# DA14585 register map
Vendor: Dialog; Series: DA1458x; File version: 1.2
CPU: CM0 r1p0, little endian, MPU, FPU, 3 interrupt priority bits
Registers are 16-bit, read-write, reset 0x0 unless marked. A register's access mark holds for its fields unless they carry their own. Offsets are from the block's base; [hi:lo] are bit positions.

## crg580_nl01 — crg580_nl01 registers
Base 0x50000000
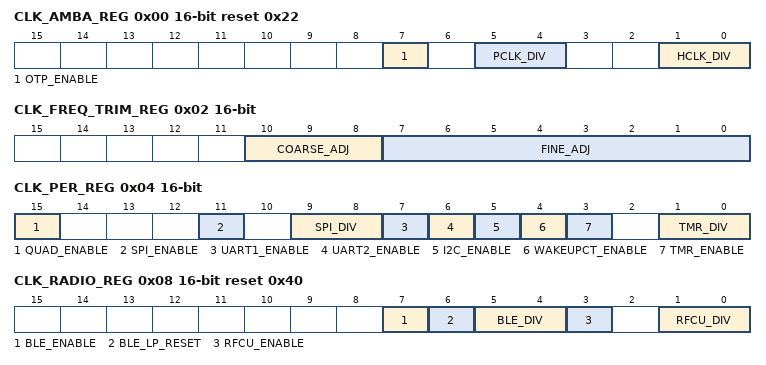
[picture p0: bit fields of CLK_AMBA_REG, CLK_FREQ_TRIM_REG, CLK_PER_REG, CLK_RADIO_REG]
0x00 CLK_AMBA_REG reset 0x22 — HCLK, PCLK, divider and clock gates
  [7] OTP_ENABLE — Clock enable for OTP controller
  [5:4] PCLK_DIV — APB interface clock (PCLK). Divider is cascaded with HCLK_DIV. PCLK is HCLK divided by: 0x0: divide by 1 0x1: divide by 2 0x2: divide by 4 0x3: divide by 8
  [1:0] HCLK_DIV — AHB interface and microprocessor clock (HCLK). HCLK is source clock divided by: 0x0: divide by 1 0x1: divide by 2 0x2: divide by 4 0x3: divide by 8
0x02 CLK_FREQ_TRIM_REG — Xtal frequency trimming register
  [10:8] COARSE_ADJ — Xtal frequency course trimming register. 0x0: lowest frequency 0x7: highest frequencyIncrement or decrement the binary value with 1. Wait approximately 200 us to allow the adjustment to settle.
  [7:0] FINE_ADJ — Xtal frequency fine trimming register. 0x00: lowest frequency 0xFF: highest frequency
0x04 CLK_PER_REG — Peripheral divider register
  [15] QUAD_ENABLE — Enable the Quadrature clock
  [11] SPI_ENABLE — Enable SPI clock
  [9:8] SPI_DIV — Division factor for SPI 0x0: divide by 1 0x1: divide by 2 0x2: divide by 4 0x3: divide by 8
  [7] UART1_ENABLE — Enable UART1 clock
  [6] UART2_ENABLE — Enable UART2 clock
  [5] I2C_ENABLE — Enable I2C clock
  [4] WAKEUPCT_ENABLE — Enable Wakeup CaptureTimer clock
  [3] TMR_ENABLE — Enable TIMER0 and TIMER2 clock
  [1:0] TMR_DIV — Division factor for TIMER0 and TIMER2 0x0: divide by 1 0x1: divide by 2 0x2: divide by 4 0x3: divide by 8
0x08 CLK_RADIO_REG reset 0x40 — Radio PLL control register
  [7] BLE_ENABLE — Enable the BLE core clocks
  [6] BLE_LP_RESET — Reset for the BLE LP timer
  [5:4] BLE_DIV — Division factor for BLE core blocks 0x0: divide by 1 0x1: divide by 2 0x2: divide by 4 0x3: divide by 8 The programmed frequency should not be lower than 8 MHz and not faster than the programmed CPU clock frequency. Refer also to BLE_CNTL2_REG[BLE_CLK_SEL].
  [3] RFCU_ENABLE — Enable the RF control Unit clock
  [1:0] RFCU_DIV — Division factor for RF Control Unit 0x0: divide by 1 0x1: divide by 2 0x2: divide by 4 0x3: divide by 8 The programmed frequency must be exactly 8 MHz.
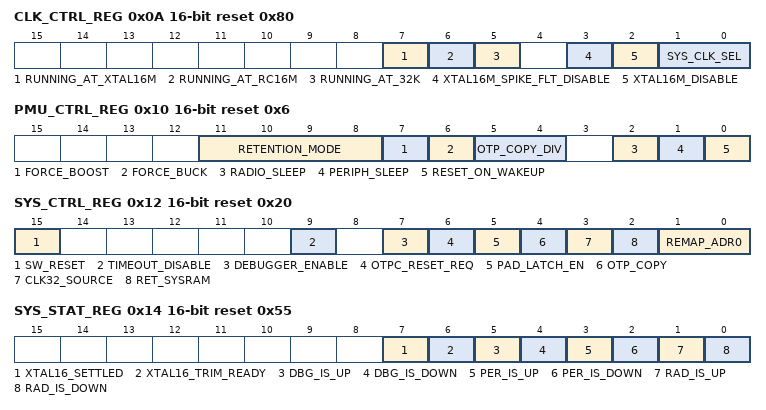
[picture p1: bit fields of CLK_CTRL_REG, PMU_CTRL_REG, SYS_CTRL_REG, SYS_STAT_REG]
0x0A CLK_CTRL_REG reset 0x80 — Clock control register
  [7] RUNNING_AT_XTAL16M ro — Indicates that the XTAL16M clock is used as clock, and may not be switched off
  [6] RUNNING_AT_RC16M ro — Indicates that the RC16M clock is used as clock
  [5] RUNNING_AT_32K ro — Indicates that either the RC32k or XTAL32k is being used as clock
  [3] XTAL16M_SPIKE_FLT_DISABLE — Disable spikefilter in digital clock
  [2] XTAL16M_DISABLE — Setting this bit instantaneously disables the 16 MHz crystal oscillator. Also, after sleep/wakeup cycle, the oscillator will not be enabled. This bit may not be set to '1'when 'RUNNING_AT_XTAL16M is '1' to prevent deadlock. After resetting this bit, wait for XTAL16_SETTLED or XTAL16_TRIM_READY to become '1' before switching to XTAL16 clock source.
  [1:0] SYS_CLK_SEL — Selects the clock source. 0x0: XTAL16M (check the XTAL16_SETTLED and XTAL16_TRIM_READY bits!!) 0x1: RC16M 0x2/0x3: either RC32k or XTAL32k is used
0x10 PMU_CTRL_REG reset 0x6 — Power Management Unit control register
  [11:8] RETENTION_MODE — Select the retainability of the 4 retention RAM macros. '1' is retainable, '0' is power gated. (3) is RETRAM4 (2) is RETRAM3 (1) is RETRAM2 (0) is RETRAM1
  [7] FORCE_BOOST — Force the DCDC into boost mode at next wakeup. Setting this bit reduces the deepsleep current. FORCE_BOOST has highest priority. When either FORCE_BOOST or FORCE_BUCK have been written, these bits cannot be changed.
  [6] FORCE_BUCK — Force the DCDC into buck mode at next wakeup. Setting this bit reduces the deepsleep current. FORCE_BOOST has highest priority. When either FORCE_BOOST or FORCE_BUCK have been written, these bits cannot be changed.
  [5:4] OTP_COPY_DIV — Sets the HCLK division during OTP mirroring
  [2] RADIO_SLEEP — Put the digital part of the radio in powerdown
  [1] PERIPH_SLEEP — Put all peripherals (I2C, UART, SPI, ADC) in powerdown
  [0] RESET_ON_WAKEUP — Perform a Hardware Reset after waking up. Booter will be started.
0x12 SYS_CTRL_REG reset 0x20 — System Control register
  [15] SW_RESET wo — Writing a '1' to this bit will reset the device, except for: SYS_CTRL_REG CLK_FREQ_TRIM_REG ...
  [9] TIMEOUT_DISABLE — Disables timeout in Power statemachine. By default, the statemachine continues if after 2 ms the blocks are not started up. This can be read back from ANA_STATUS_REG.
  [7] DEBUGGER_ENABLE — Enable the debugger. This bit is set by the booter according to the OTP header. If not set, the SWDIO and SW_CLK can be used as gpio ports.
  [6] OTPC_RESET_REQ — Reset request for the OTP controller.
  [5] PAD_LATCH_EN — Latches the control signals of the pads for state retention in powerdown mode. 0: Control signals are retained 1: Latch is transparant, pad can be recontrolled
  [4] OTP_COPY — Enables OTP to SysRAM copy action after waking up PD_SYS
  [3] CLK32_SOURCE — Sets the clock source of the 32 kHz clock 0 = RC-oscillator 1 = 32 kHz crystal oscillator
  [2] RET_SYSRAM — Sets the development phase mode. If this bit is set, the SysRAM cell will not power gated during sleep (extended sleep). No copy action to SysRAM is done when the system wakes up. For emulating startup time, the OTP_COPY bit still needs to be set.
  [1:0] REMAP_ADR0 — Controls which memory is located at address 0x0000 for execution. 0x0: ROM 0x1: OTP 0x2: SysRAM 0x3: RetRAM
0x14 SYS_STAT_REG reset 0x55 — System status register
  [7] XTAL16_SETTLED ro — Indicates that XTAL16 has had > 2 ms of settle time
  [6] XTAL16_TRIM_READY ro — Indicates that XTAL trimming mechanism is ready, i.e. the trimming equals CLK_FREQ_TRIM_REG.
  [5] DBG_IS_UP ro — Indicates that PD_DBG is functional
  [4] DBG_IS_DOWN ro — Indicates that PD_DBG is in power down
  [3] PER_IS_UP ro — Indicates that PD_PER is functional
  [2] PER_IS_DOWN ro — Indicates that PD_PER is in power down
  [1] RAD_IS_UP ro — Indicates that PD_RAD is functional
  [0] RAD_IS_DOWN ro — Indicates that PD_RAD is in power down
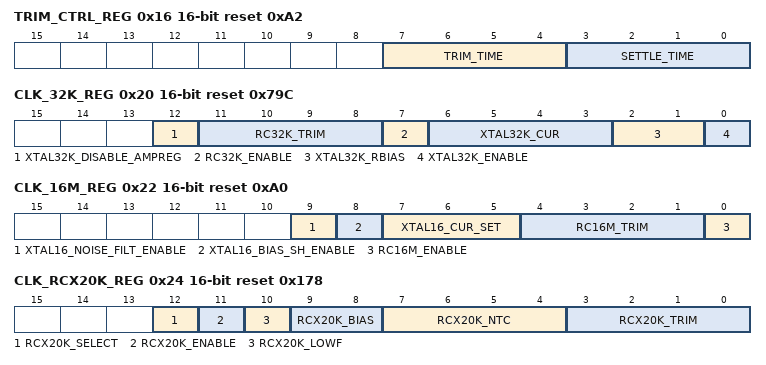
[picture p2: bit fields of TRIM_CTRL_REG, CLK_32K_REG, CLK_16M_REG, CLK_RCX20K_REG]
0x16 TRIM_CTRL_REG reset 0xA2 — Control trimming of the XTAL16M
  [7:4] TRIM_TIME — Defines the delay between XTAL16M enable and applying the CLK_FREQ_TRIM_REG in steps of 250 us. 0x0: apply directly 0x1: wait between 0 and 250 us 0x2: wait between 250 us and 500 us etc.
  [3:0] SETTLE_TIME — Defines the delay between applying CLK_FREQ_TRIM_REG and XTAL16_SETTLED in steps of 250 us. 0x0: XTAL16_SETTLED is set direcly 0x1: wait between 0 and 250 us 0x2: wait between 250 us and 500 us etc.
0x20 CLK_32K_REG reset 0x79C — 32 kHz oscillator register
  [12] XTAL32K_DISABLE_AMPREG — Setting this bit disables the amplitude regulation of the XTAL32kHz oscillator. Set this bit to '1' for an external clock applied at XTAL32Kp. Keep this bit '0' with a crystal between XTAL32Kp and XTAL32Km.
  [11:8] RC32K_TRIM — Controls the frequency of the RC32K oscillator. 0x0: lowest frequency 0x7: default 0xF: highest frequency
  [7] RC32K_ENABLE — Enables the 32 kHz RC oscillator
  [6:3] XTAL32K_CUR — Bias current for the 32kHz XTAL oscillator. 0x0: minimum 0x3: default 0xF: maximum For each application there is an optimal setting for which the startup behaviour is optimal.
  [2:1] XTAL32K_RBIAS — Setting for the bias resistor of the 32 kHz XTAL oscillator. 0x0: maximum 0x3: minimum Prefered setting will be provided by Dialog.
  [0] XTAL32K_ENABLE — Enables the 32 kHz XTAL oscillator
0x22 CLK_16M_REG reset 0xA0 — 16 MHz RC-oscillator register
  [9] XTAL16_NOISE_FILT_ENABLE — Enables noise flter in 16 MHz crystal oscillator
  [8] XTAL16_BIAS_SH_ENABLE — Enables Ibias sample/hold function in 16 MHz crystal oscillator. This bit should be set when the system wake up and reset before entering deep or extended sleep mode.
  [7:5] XTAL16_CUR_SET — Bias current for the 16 MHz XTAL oscillator. 0x0: minimum 0x7: maximum
  [4:1] RC16M_TRIM — Controls the frequency of the RC16M oscillator. 0x0: lowest frequency 0xF: highest frequency
  [0] RC16M_ENABLE — Enables the 16 MHz RC oscillator
0x24 CLK_RCX20K_REG reset 0x178 — RCX-oscillator control register
  [12] RCX20K_SELECT — Selects RCX oscillator. 0 : RC32K oscillator 1: RCX oscillator
  [11] RCX20K_ENABLE — Enable the RCX oscillator
  [10] RCX20K_LOWF — Extra low frequency
  [9:8] RCX20K_BIAS — Bias control
  [7:4] RCX20K_NTC — Temperature control
  [3:0] RCX20K_TRIM — Controls the frequency of the RCX oscillator. 0x0: lowest frequency 0x7: default 0xF: highest frequency
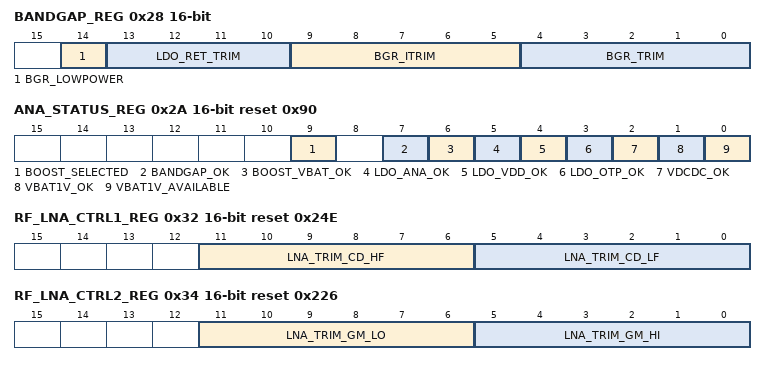
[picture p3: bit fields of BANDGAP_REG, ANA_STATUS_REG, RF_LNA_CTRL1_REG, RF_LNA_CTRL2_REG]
0x28 BANDGAP_REG — Bandgap trimming
  [14] BGR_LOWPOWER — Test-mode, do not use. It disables the bandgap core (voltages will continue for some time, but will slowely drift away)
  [13:10] LDO_RET_TRIM
  [9:5] BGR_ITRIM — Current trimming for bias
  [4:0] BGR_TRIM — Trim register for bandgap
0x2A ANA_STATUS_REG reset 0x90 — Status bit of analog (power management) circuits
  [9] BOOST_SELECTED ro — Indicates that DCDC is in boost mode
  [7] BANDGAP_OK ro — Indicates that BANDGAP is OK
  [6] BOOST_VBAT_OK ro — Indicates that VBAT is above threshold while in BOOST converter mode.
  [5] LDO_ANA_OK ro — Indicates that LDO_ANA is in regulation. This LDO is used for the general-purpose ADC only
  [4] LDO_VDD_OK ro — Indicates that LDO_VDD is in regulation
  [3] LDO_OTP_OK ro — Indicates that LDO_OTP is in regulation
  [2] VDCDC_OK ro — Indicates that VDCDC is above threshold.
  [1] VBAT1V_OK ro — Indicates that VBAT1V is above threshold.
  [0] VBAT1V_AVAILABLE ro — Indicates that VBAT1V is available.
0x30 RF_IO_CTRL1_REG reset 0xF — (in CRG)
  [7:0] RFIO_TRIM1_CAP — Trim the RFIO input capacitance 00: Minimum capacitance 10: Nominal capacitance 1F: Maximal capacitance
0x32 RF_LNA_CTRL1_REG reset 0x24E — (in CRG)
  [11:6] LNA_TRIM_CD_HF — Trim the LNA output capacitance for CN > 19 00: Minimum capacitance 10: Nominal capacitance 1F: Maximal capacitance
  [5:0] LNA_TRIM_CD_LF — Trim the LNA output capacitance for CN 00: Minimum capacitance 10: Nominal capacitance 1F: Maximal capacitance
0x34 RF_LNA_CTRL2_REG reset 0x226 — (in CRG)
  [11:6] LNA_TRIM_GM_LO — Trim the LNA bias resistor for optimum transcunductance (gain) in AGC settings 2 and 3 00: Minimum transconductance 10: Nominal transconductance 1F: Maximal transconductance
  [5:0] LNA_TRIM_GM_HI — Trim the LNA bias resistor for optimum transcunductance (gain) in AGC settings 0 and 1 00: Minimum transconductance 10: Nominal transconductance 1F: Maximal transconductance
0x36 RF_LNA_CTRL3_REG reset 0x7 — (in CRG)
  [4:0] LNA_TRIM_CGS — Trim the LNA gate-source capacitance 00: Minimum capacitance 10: Nominal capacitance 1F: Maximal capacitance
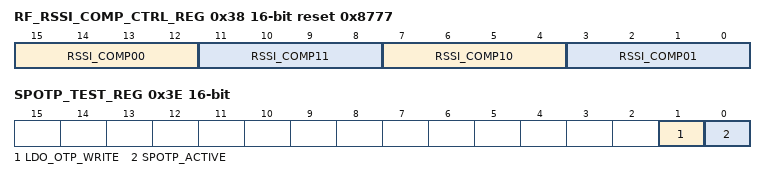
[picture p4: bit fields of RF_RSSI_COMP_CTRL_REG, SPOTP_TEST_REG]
0x38 RF_RSSI_COMP_CTRL_REG reset 0x8777 — (in CRG)
  [15:12] RSSI_COMP00 — RSSI compensation value for LNA gain setting 00 '0x0': -8 '0x1': -7 '0x2': -6 '0x3': -5 '0x4': -4 '0x5': -3 '0x6': -2 '0x7': -1 '0x8': 0 (reset) '0x9': 1 '0xA': 2 '0xB': 3 '0xC': 4 '0xD': 5 '0xE': 6 '0xF': 7
  [11:8] RSSI_COMP11 — RSSI compensation value for LNA gain setting 11 relative to 00 Coding identical to RSSI_COMP01.
  [7:4] RSSI_COMP10 — RSSI compensation value for LNA gain setting 10 relative to 00 Coding identical to RSSI_COMP01.
  [3:0] RSSI_COMP01 — RSSI compensation value for LNA gain setting 01 relative to 00 '0x0': -4 '0x1': -3 '0x2': -2 '0x3': -1 '0x4': 0 '0x5': 1 '0x6': 2 '0x7': 3 (reset) '0x8': 4 '0x9': 5 '0xA': 6 '0xB': 7 '0xC': 8 '0xD': 9 '0xE': 10 '0xF': 11
0x3A RF_VCO_CTRL_REG reset 0x1
  [3:0] VCO_AMPL_SET — Set the desired amplitude of the VCO'0': minimum amplitude '4': default amplitude 'F': maximum amplitude
0x3E SPOTP_TEST_REG — (in CRG)
  [1] LDO_OTP_WRITE — Bypass LDO and put VBAT directly on OTP_VDDIO
  [0] SPOTP_ACTIVE — Enables the SPOTP testmode. Reset by write or PowerOnReset
